# LM3S9790 register map
File version: 7944
Registers are 32-bit, read-write, no defined reset value unless marked. A register's access mark holds for its fields unless they carry their own. Offsets are from the block's base; [hi:lo] are bit positions.

## I2S0 — Register map for I2S0 peripheral
Base 0x40054000; register names take the prefix I2S0
0x00 TXFIFO wo — I2S Transmit FIFO Data
  [31:0] I2S_TXFIFO — TX Data
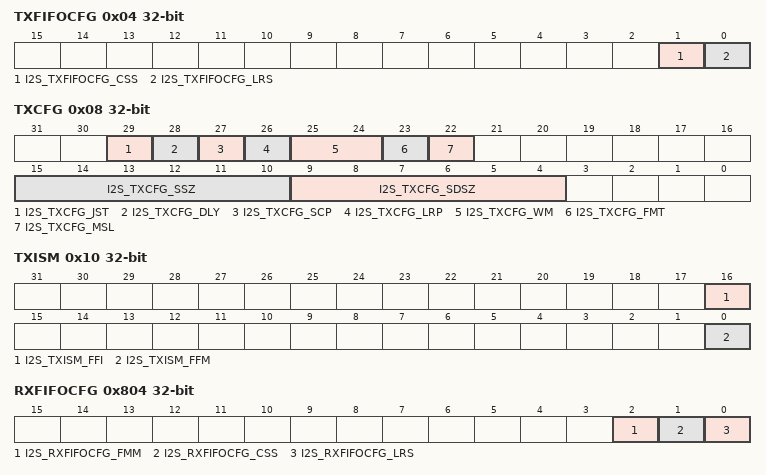
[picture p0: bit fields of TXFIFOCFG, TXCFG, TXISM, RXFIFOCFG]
0x04 TXFIFOCFG — I2S Transmit FIFO Configuration
  [1] I2S_TXFIFOCFG_CSS — Compact Stereo Sample Size
  [0] I2S_TXFIFOCFG_LRS — Left-Right Sample Indicator
0x08 TXCFG — I2S Transmit Module Configuration
  [29] I2S_TXCFG_JST — Justification of Output Data
  [28] I2S_TXCFG_DLY — Data Delay
  [27] I2S_TXCFG_SCP — SCLK Polarity
  [26] I2S_TXCFG_LRP — Left/Right Clock Polarity
  [25:24] I2S_TXCFG_WM — Write Mode
    0=I2S_TXCFG_WM_DUAL (Stereo mode); 1=I2S_TXCFG_WM_COMPACT (Compact Stereo mode); 2=I2S_TXCFG_WM_MONO (Mono mode)
  [23] I2S_TXCFG_FMT — FIFO Empty
  [22] I2S_TXCFG_MSL — SCLK Master/Slave
  [15:10] I2S_TXCFG_SSZ — Sample Size
  [9:4] I2S_TXCFG_SDSZ — System Data Size
0x0C TXLIMIT — I2S Transmit FIFO Limit
  [4:0] I2S_TXLIMIT_LIMIT — FIFO Limit
0x10 TXISM — I2S Transmit Interrupt Status and Mask
  [16] I2S_TXISM_FFI — Transmit FIFO Service Request Interrupt
  [0] I2S_TXISM_FFM — FIFO Interrupt Mask
0x18 TXLEV — I2S Transmit FIFO Level
  [4:0] I2S_TXLEV_LEVEL — Number of Audio Samples
0x800 RXFIFO — I2S Receive FIFO Data
  [31:0] I2S_RXFIFO — RX Data
0x804 RXFIFOCFG — I2S Receive FIFO Configuration
  [2] I2S_RXFIFOCFG_FMM — FIFO Mono Mode
  [1] I2S_RXFIFOCFG_CSS — Compact Stereo Sample Size
  [0] I2S_RXFIFOCFG_LRS — Left-Right Sample Indicator
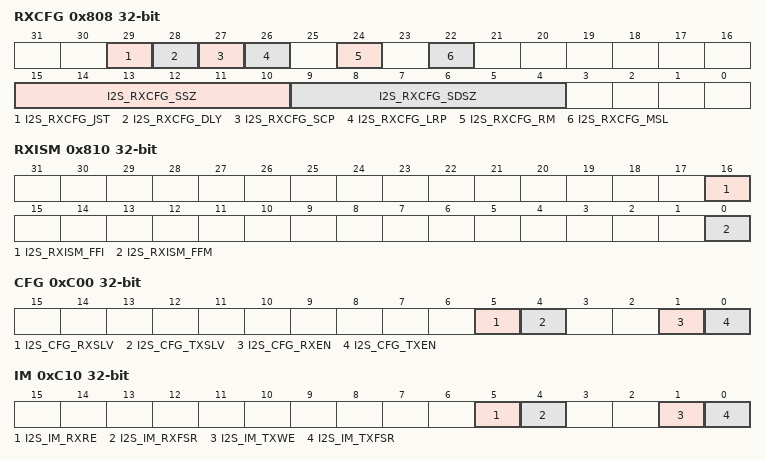
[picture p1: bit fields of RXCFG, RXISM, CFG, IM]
0x808 RXCFG — I2S Receive Module Configuration
  [29] I2S_RXCFG_JST — Justification of Input Data
  [28] I2S_RXCFG_DLY — Data Delay
  [27] I2S_RXCFG_SCP — SCLK Polarity
  [26] I2S_RXCFG_LRP — Left/Right Clock Polarity
  [24] I2S_RXCFG_RM — Read Mode
  [22] I2S_RXCFG_MSL — SCLK Master/Slave
  [15:10] I2S_RXCFG_SSZ — Sample Size
  [9:4] I2S_RXCFG_SDSZ — System Data Size
0x80C RXLIMIT — I2S Receive FIFO Limit
  [4:0] I2S_RXLIMIT_LIMIT — FIFO Limit
0x810 RXISM — I2S Receive Interrupt Status and Mask
  [16] I2S_RXISM_FFI — Receive FIFO Service Request Interrupt
  [0] I2S_RXISM_FFM — FIFO Interrupt Mask
0x818 RXLEV — I2S Receive FIFO Level
  [4:0] I2S_RXLEV_LEVEL — Number of Audio Samples
0xC00 CFG — I2S Module Configuration
  [5] I2S_CFG_RXSLV — Use External I2S0RXMCLK
  [4] I2S_CFG_TXSLV — Use External I2S0TXMCLK
  [1] I2S_CFG_RXEN — Serial Receive Engine Enable
  [0] I2S_CFG_TXEN — Serial Transmit Engine Enable
0xC10 IM — I2S Interrupt Mask
  [5] I2S_IM_RXRE — Receive FIFO Read Error
  [4] I2S_IM_RXFSR — Receive FIFO Service Request
  [1] I2S_IM_TXWE — Transmit FIFO Write Error
  [0] I2S_IM_TXFSR — Transmit FIFO Service Request
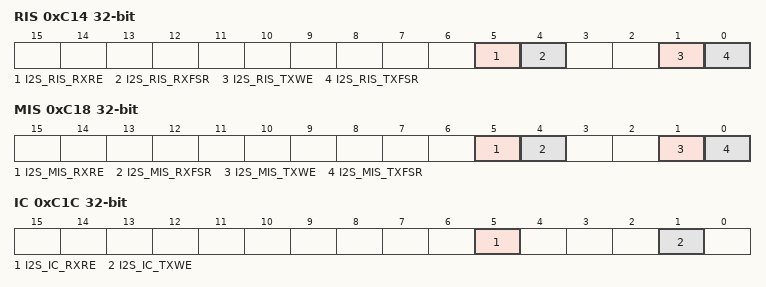
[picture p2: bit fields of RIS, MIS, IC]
0xC14 RIS — I2S Raw Interrupt Status
  [5] I2S_RIS_RXRE — Receive FIFO Read Error
  [4] I2S_RIS_RXFSR — Receive FIFO Service Request
  [1] I2S_RIS_TXWE — Transmit FIFO Write Error
  [0] I2S_RIS_TXFSR — Transmit FIFO Service Request
0xC18 MIS — I2S Masked Interrupt Status
  [5] I2S_MIS_RXRE — Receive FIFO Read Error
  [4] I2S_MIS_RXFSR — Receive FIFO Service Request
  [1] I2S_MIS_TXWE — Transmit FIFO Write Error
  [0] I2S_MIS_TXFSR — Transmit FIFO Service Request
0xC1C IC wo — I2S Interrupt Clear
  [5] I2S_IC_RXRE — Receive FIFO Read Error
  [1] I2S_IC_TXWE — Transmit FIFO Write Error

## HIB — Register map for HIB peripheral
Base 0x400FC000; register names take the prefix HIB
0x00 RTCC — Hibernation RTC Counter
  [31:0] HIB_RTCC — RTC Counter
0x04 RTCM0 — Hibernation RTC Match 0
  [31:0] HIB_RTCM0 — RTC Match 0
0x08 RTCM1 — Hibernation RTC Match 1
  [31:0] HIB_RTCM1 — RTC Match 1
0x0C RTCLD — Hibernation RTC Load
  [31:0] HIB_RTCLD — RTC Load
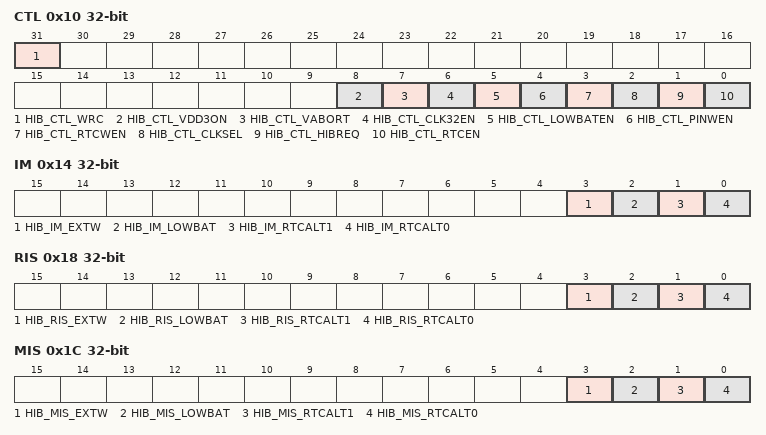
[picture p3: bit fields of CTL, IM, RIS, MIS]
0x10 CTL — Hibernation Control
  [31] HIB_CTL_WRC — Write Complete/Capable
  [8] HIB_CTL_VDD3ON — VDD Powered
  [7] HIB_CTL_VABORT — Power Cut Abort Enable
  [6] HIB_CTL_CLK32EN — Clocking Enable
  [5] HIB_CTL_LOWBATEN — Low Battery Monitoring Enable
  [4] HIB_CTL_PINWEN — External WAKE Pin Enable
  [3] HIB_CTL_RTCWEN — RTC Wake-up Enable
  [2] HIB_CTL_CLKSEL — Hibernation Module Clock Select
  [1] HIB_CTL_HIBREQ — Hibernation Request
  [0] HIB_CTL_RTCEN — RTC Timer Enable
0x14 IM — Hibernation Interrupt Mask
  [3] HIB_IM_EXTW — External Wake-Up Interrupt Mask
  [2] HIB_IM_LOWBAT — Low Battery Voltage Interrupt Mask
  [1] HIB_IM_RTCALT1 — RTC Alert 1 Interrupt Mask
  [0] HIB_IM_RTCALT0 — RTC Alert 0 Interrupt Mask
0x18 RIS — Hibernation Raw Interrupt Status
  [3] HIB_RIS_EXTW — External Wake-Up Raw Interrupt Status
  [2] HIB_RIS_LOWBAT — Low Battery Voltage Raw Interrupt Status
  [1] HIB_RIS_RTCALT1 — RTC Alert 1 Raw Interrupt Status
  [0] HIB_RIS_RTCALT0 — RTC Alert 0 Raw Interrupt Status
0x1C MIS — Hibernation Masked Interrupt Status
  [3] HIB_MIS_EXTW — External Wake-Up Masked Interrupt Status
  [2] HIB_MIS_LOWBAT — Low Battery Voltage Masked Interrupt Status
  [1] HIB_MIS_RTCALT1 — RTC Alert 1 Masked Interrupt Status
  [0] HIB_MIS_RTCALT0 — RTC Alert 0 Masked Interrupt Status
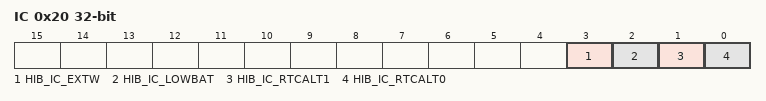
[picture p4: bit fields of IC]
0x20 IC — Hibernation Interrupt Clear
  [3] HIB_IC_EXTW — External Wake-Up Masked Interrupt Clear
  [2] HIB_IC_LOWBAT — Low Battery Voltage Masked Interrupt Clear
  [1] HIB_IC_RTCALT1 — RTC Alert1 Masked Interrupt Clear
  [0] HIB_IC_RTCALT0 — RTC Alert0 Masked Interrupt Clear
0x24 RTCT — Hibernation RTC Trim
  [15:0] HIB_RTCT_TRIM — RTC Trim Value
0x30 DATA — Hibernation Data
  [31:0] HIB_DATA_RTD — Hibernation Module NV Data
